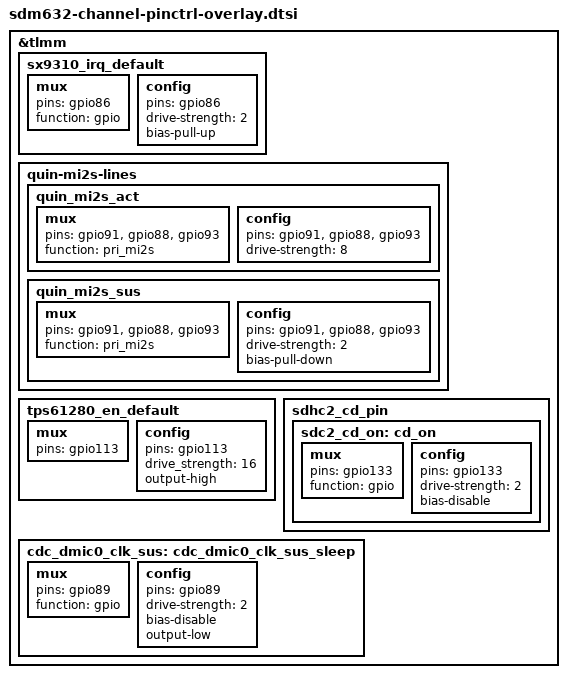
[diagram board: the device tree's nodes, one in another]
/*
 * Copyright (c) 2017-2018, The Linux Foundation. All rights reserved.
 *
 * This program is free software; you can redistribute it and/or modify
 * it under the terms of the GNU General Public License version 2 and
 * only version 2 as published by the Free Software Foundation.
 *
 * This program is distributed in the hope that it will be useful,
 * but WITHOUT ANY WARRANTY; without even the implied warranty of
 * MERCHANTABILITY or FITNESS FOR A PARTICULAR PURPOSE.  See the
 * GNU General Public License for more details.
 */

&tlmm {
	sx9310_irq_default: sx9310_irq_default {
		mux {
			pins = "gpio86";
			function = "gpio";
		};
		config {
			pins = "gpio86";
			drive-strength = <2>;
			bias-pull-up;
		};
	};

	quin-mi2s-lines {
		quin_mi2s_act: quin_mi2s_act {
			mux {
				pins = "gpio91", "gpio88", "gpio93";
				function = "pri_mi2s";
			};
			config {
				pins = "gpio91", "gpio88", "gpio93";
				drive-strength = <8>;
			};
		};
		quin_mi2s_sus: quin_mi2s_sus {
			mux {
				pins = "gpio91", "gpio88", "gpio93";
				function = "pri_mi2s";
			};
			config {
				pins = "gpio91", "gpio88", "gpio93";
				drive-strength = <2>;
				bias-pull-down;
			};
		};
	};

	tps61280_en_default: tps61280_en_default {
		mux {
			pins = "gpio113";
		};
		config {
			pins = "gpio113";
			drive_strength = <16>;
			output-high;
		};
	};

	sdhc2_cd_pin {
		sdc2_cd_on: cd_on {
			mux {
				pins = "gpio133";
				function = "gpio";
			};

			config {
				pins = "gpio133";
				drive-strength = <2>;
				/delete-property/ bias-pull-up;
				bias-disable;
			};
		};
	};

	cdc_dmic0_clk_sus: cdc_dmic0_clk_sus_sleep {
		mux {
			pins = "gpio89";
			function = "gpio";
		};

		config {
			pins = "gpio89";
			drive-strength = <2>;
			bias-disable;
			output-low;
		};
	};
};
